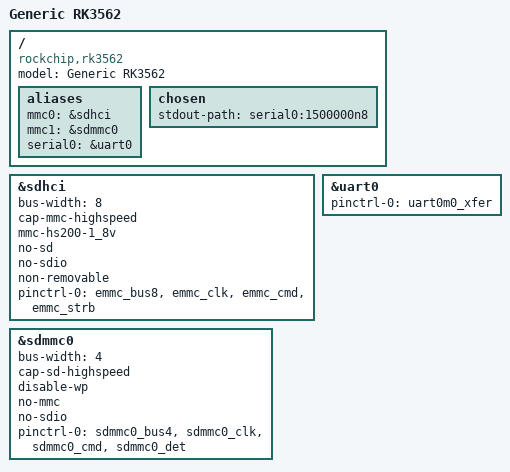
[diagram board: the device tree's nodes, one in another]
// SPDX-License-Identifier: (GPL-2.0+ OR MIT)
/*
 * Minimal generic DT for RK3562 with eMMC and SD-card enabled
 */

/dts-v1/;
#include "rk3562.dtsi"

/ {
	model = "Generic RK3562";
	compatible = "rockchip,rk3562";

	aliases {
		mmc0 = &sdhci;
		mmc1 = &sdmmc0;
		serial0 = &uart0;
	};

	chosen {
		stdout-path = "serial0:1500000n8";
	};
};

&sdhci {
	bus-width = <8>;
	cap-mmc-highspeed;
	mmc-hs200-1_8v;
	no-sd;
	no-sdio;
	non-removable;
	pinctrl-names = "default";
	pinctrl-0 = <&emmc_bus8>, <&emmc_clk>, <&emmc_cmd>, <&emmc_strb>;
	status = "okay";
};

&sdmmc0 {
	bus-width = <4>;
	cap-sd-highspeed;
	disable-wp;
	no-mmc;
	no-sdio;
	pinctrl-names = "default";
	pinctrl-0 = <&sdmmc0_bus4>, <&sdmmc0_clk>, <&sdmmc0_cmd>, <&sdmmc0_det>;
	status = "okay";
};

&uart0 {
	pinctrl-names = "default";
	pinctrl-0 = <&uart0m0_xfer>;
	status = "okay";
};
